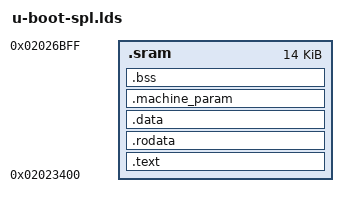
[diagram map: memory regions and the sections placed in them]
/*
 * (C) Copyright 2002
 * Gary Jennejohn, DENX Software Engineering, <garyj@denx.de>
 *
 * Copyright (C) 2012 Samsung Electronics
 *
 * Based on arch/arm/cpu/armv7/omap-common/u-boot-spl.lds
 *
 * See file CREDITS for list of people who contributed to this
 * project.
 *
 * This program is free software; you can redistribute it and/or
 * modify it under the terms of the GNU General Public License as
 * published by the Free Software Foundation; either version 2 of
 * the License, or (at your option) any later version.
 *
 * This program is distributed in the hope that it will be useful,
 * but WITHOUT ANY WARRANTY; without even the implied warranty of
 * MERCHANTABILITY or FITNESS FOR A PARTICULAR PURPOSE. See the
 * GNU General Public License for more details.
 *
 * You should have received a copy of the GNU General Public License
 * along with this program; if not, write to the Free Software
 * Foundation, Inc., 59 Temple Place, Suite 330, Boston,
 * MA 02111-1307 USA
 */

/* FIXME: i was originally trying to use this, but decided to use the
   x86 romstage.ld as a template instead */
/* FIXME: linker was unhappy using CONFIG_SPL_* for some reason., even
   though they show up in build/ldoptions.
MEMORY { .sram : ORIGIN = CONFIG_SPL_TEXT_BASE,
		LENGTH = CONFIG_SPL_MAX_SIZE }
*/

MEMORY { .sram : ORIGIN = 0x02023400, LENGTH = 0x3800 }

OUTPUT_FORMAT("elf32-littlearm", "elf32-littlearm", "elf32-littlearm")
OUTPUT_ARCH(arm)
ENTRY(_start)

SECTIONS
{
	.text :
	{
		__start = .;
		src/arch/armv7/lib/start.o (.text)
		*(.text*)
	} >.sram
	. = ALIGN(4);

	.rodata : { *(SORT_BY_ALIGNMENT(.rodata*)) } >.sram
	. = ALIGN(4);

	.data : { *(SORT_BY_ALIGNMENT(.data*)) } >.sram
	. = ALIGN(4);

	/* Align .machine_param on 256 byte boundary for easier searching */
	.machine_param ALIGN(0x100) : { *(.machine_param) } >.sram
	. = ALIGN(4);

	__image_copy_end = .;
	_end = .;

	.bss :
	{
		. = ALIGN(4);
		__bss_start = .;
		*(.bss*)
		. = ALIGN(4);
		__bss_end__ = .;
	} >.sram
}
